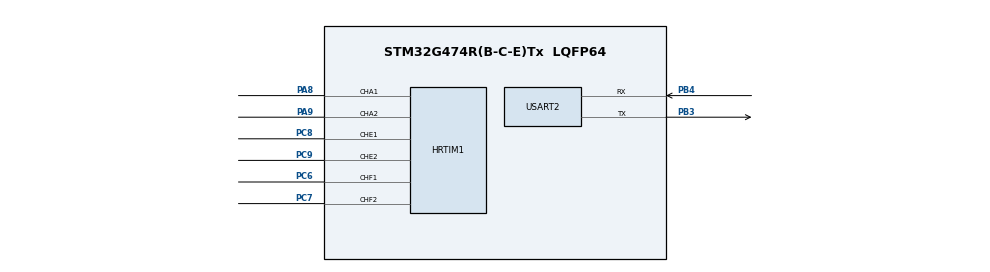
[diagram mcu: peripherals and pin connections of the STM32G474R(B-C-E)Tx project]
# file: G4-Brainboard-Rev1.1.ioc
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Dma.Request0=USART2_RX
Dma.USART2_RX.0.Direction=DMA_PERIPH_TO_MEMORY
Dma.USART2_RX.0.EventEnable=DISABLE
Dma.USART2_RX.0.Instance=DMA1_Channel1
Dma.USART2_RX.0.MemDataAlignment=DMA_MDATAALIGN_BYTE
Dma.USART2_RX.0.MemInc=DMA_MINC_ENABLE
Dma.USART2_RX.0.Mode=DMA_CIRCULAR
Dma.USART2_RX.0.PeriphDataAlignment=DMA_PDATAALIGN_BYTE
Dma.USART2_RX.0.PeriphInc=DMA_PINC_DISABLE
Dma.USART2_RX.0.Polarity=HAL_DMAMUX_REQ_GEN_RISING
Dma.USART2_RX.0.Priority=DMA_PRIORITY_LOW
Dma.USART2_RX.0.RequestNumber=1
Dma.USART2_RX.0.SignalID=NONE
Dma.USART2_RX.0.SyncEnable=DISABLE
Dma.USART2_RX.0.SyncPolarity=HAL_DMAMUX_SYNC_NO_EVENT
Dma.USART2_RX.0.SyncRequestNumber=1
Dma.USART2_RX.0.SyncSignalID=NONE
HRTIM1.CompareUnit1-Output_TA1TA2=HRTIM_COMPAREUNIT_1
HRTIM1.CompareUnit1-Output_TE1TE2=HRTIM_COMPAREUNIT_1
HRTIM1.CompareUnit1-Output_TF1TF2=HRTIM_COMPAREUNIT_1
HRTIM1.CompareValue1-Output_TA1TA2=48
HRTIM1.CompareValue1-Output_TE1TE2=27200
HRTIM1.CompareValue1-Output_TF1TF2=54352
HRTIM1.DeadTimeInsertion-Output_TA1TA2=HRTIM_TIMDEADTIMEINSERTION_ENABLED
HRTIM1.DeadTimeInsertion-Output_TE1TE2=HRTIM_TIMDEADTIMEINSERTION_ENABLED
HRTIM1.DeadTimeInsertion-Output_TF1TF2=HRTIM_TIMDEADTIMEINSERTION_ENABLED
HRTIM1.FallingValue-Output_TA1TA2=0x0
HRTIM1.IdleLevel1-Output_TF1TF2=HRTIM_OUTPUTIDLELEVEL_INACTIVE
HRTIM1.NumberResetSource1-Output_TA1TA2=1
HRTIM1.NumberResetSource1-Output_TE1TE2=1
HRTIM1.NumberResetSource1-Output_TF1TF2=1
HRTIM1.NumberSetSource1-Output_TA1TA2=0
HRTIM1.NumberSetSource1-Output_TE1TE2=0
HRTIM1.NumberSetSource1-Output_TF1TF2=0
HRTIM1.NumberUpdateTrigger-Output_TA1TA2=0
HRTIM1.Periode_TA=54400
HRTIM1.Periode_TE=54400
HRTIM1.Periode_TF=54400
HRTIM1.PreloadEnable-Output_TA1TA2=HRTIM_PRELOAD_ENABLED
HRTIM1.PreloadEnable-Output_TE1TE2=HRTIM_PRELOAD_ENABLED
HRTIM1.PreloadEnable-Output_TF1TF2=HRTIM_PRELOAD_ENABLED
HRTIM1.PrescalerDead-Output_TA1TA2=HRTIM_TIMDEADTIME_PRESCALERRATIO_DIV1
HRTIM1.PrescalerDead-Output_TE1TE2=HRTIM_TIMDEADTIME_PRESCALERRATIO_DIV1
HRTIM1.PrescalerDead-Output_TF1TF2=HRTIM_TIMDEADTIME_PRESCALERRATIO_DIV1
HRTIM1.PrescalerRatio_TA=HRTIM_PRESCALERRATIO_MUL16
HRTIM1.PrescalerRatio_TE=HRTIM_PRESCALERRATIO_MUL16
HRTIM1.PrescalerRatio_TF=HRTIM_PRESCALERRATIO_MUL16
HRTIM1.ResetOutput1_Source1-Output_TA1TA2=HRTIM_OUTPUTRESET_TIMCMP1
HRTIM1.ResetOutput1_Source1-Output_TE1TE2=HRTIM_OUTPUTRESET_TIMCMP1
HRTIM1.ResetOutput1_Source1-Output_TF1TF2=HRTIM_OUTPUTRESET_TIMCMP1
HRTIM1.ResetUpdate-Output_TA1TA2=HRTIM_TIMUPDATEONRESET_ENABLED
HRTIM1.ResetUpdate-Output_TE1TE2=HRTIM_TIMUPDATEONRESET_ENABLED
HRTIM1.ResetUpdate-Output_TF1TF2=HRTIM_TIMUPDATEONRESET_ENABLED
HRTIM1.RisingValue-Output_TA1TA2=0x0
HRTIM1.UpDownMode-Output_TA1TA2=HRTIM_TIMERUPDOWNMODE_UPDOWN
HRTIM1.UpDownMode-Output_TE1TE2=HRTIM_TIMERUPDOWNMODE_UPDOWN
HRTIM1.UpDownMode-Output_TF1TF2=HRTIM_TIMERUPDOWNMODE_UPDOWN
Mcu.Family=STM32G4
Mcu.Name=STM32G474R(B-C-E)Tx
Mcu.Package=LQFP64
NVIC.DMA1_Channel1_IRQn=true\:0\:0\:false\:false\:false\:true\:true\:true
NVIC.PriorityGroup=NVIC_PRIORITYGROUP_4
NVIC.USART2_IRQn=true\:0\:0\:false\:false\:false\:true\:true\:true
PA8.Mode=Output_TA1TA2
PA8.Signal=HRTIM1_CHA1
PA9.Mode=Output_TA1TA2
PA9.Signal=HRTIM1_CHA2
PB3.Mode=Asynchronous
PB3.Signal=USART2_TX
PB4.Mode=Asynchronous
PB4.Signal=USART2_RX
PC6.Mode=Output_TF1TF2
PC6.Signal=HRTIM1_CHF1
PC7.Mode=Output_TF1TF2
PC7.Signal=HRTIM1_CHF2
PC8.Mode=Output_TE1TE2
PC8.Signal=HRTIM1_CHE1
PC9.Mode=Output_TE1TE2
PC9.Signal=HRTIM1_CHE2
ProjectManager.HeapSize=0x200
ProjectManager.StackSize=0x400
ProjectManager.TargetToolchain=Makefile
RCC.ADC12Freq_Value=170000000
RCC.ADC345Freq_Value=170000000
RCC.AHBFreq_Value=170000000
RCC.APB1Freq_Value=170000000
RCC.APB1TimFreq_Value=170000000
RCC.APB2Freq_Value=170000000
RCC.APB2TimFreq_Value=170000000
RCC.CortexFreq_Value=170000000
RCC.EXTERNAL_CLOCK_VALUE=12288000
RCC.HCLKFreq_Value=170000000
RCC.HSE_VALUE=16000000
RCC.HSI48_VALUE=48000000
RCC.HSI_VALUE=16000000
RCC.LSE_VALUE=32768
RCC.PLLM=RCC_PLLM_DIV4
RCC.PLLN=85
RCC.SYSCLKFreq_VALUE=170000000
RCC.SYSCLKSource=RCC_SYSCLKSOURCE_PLLCLK
RCC.USBFreq_Value=170000000
RCC.VCOOutputFreq_Value=340000000
USART2.OneBitSampling=UART_ONE_BIT_SAMPLE_DISABLE
USART2.VirtualMode-Asynchronous=VM_ASYNC
VP_SYS_VS_DBSignals.Mode=DisableDeadBatterySignals
board=custom

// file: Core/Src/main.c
/* USER CODE BEGIN Header */
/**
  ******************************************************************************
  * @file           : main.c
  * @brief          : Main program body
  ******************************************************************************
  * @attention
  *
  * Copyright (c) 2026 STMicroelectronics.
  * All rights reserved.
  *
  * This software is licensed under terms that can be found in the LICENSE file
  * in the root directory of this software component.
  * If no LICENSE file comes with this software, it is provided AS-IS.
  *
  ******************************************************************************
  */
/* USER CODE END Header */
#include "main.h"
#include "dma.h"
#include "hrtim.h"
#include "usart.h"
#include "gpio.h"

/* USER CODE BEGIN PD */

/**
 * \brief           Calculate length of statically allocated array
 */
#define ARRAY_LEN(x) (sizeof(x) / sizeof((x)[0]))

/* USER CODE END PD */

/* USER CODE BEGIN PV */

/**
 * \brief           Circular DMA Buffer for USART2 RX
 */
uint8_t usart2_rx_dma_buff[256];

/* USER CODE END PV */

void SystemClock_Config(void);

int main(void)
{

  /* MCU Configuration--------------------------------------------------------*/

  /* Reset of all peripherals, Initializes the Flash interface and the Systick. */
  LL_APB2_GRP1_EnableClock(LL_APB2_GRP1_PERIPH_SYSCFG);
  LL_APB1_GRP1_EnableClock(LL_APB1_GRP1_PERIPH_PWR);

  /* System interrupt init*/
  NVIC_SetPriorityGrouping(NVIC_PRIORITYGROUP_4);

  /* SysTick_IRQn interrupt configuration */
  NVIC_SetPriority(SysTick_IRQn, NVIC_EncodePriority(NVIC_GetPriorityGrouping(),15, 0));

  /** Disable the internal Pull-Up in Dead Battery pins of UCPD peripheral
  */
  LL_PWR_DisableUCPDDeadBattery();

  /* Configure the system clock */
  SystemClock_Config();

  /* Initialize all configured peripherals */
  MX_GPIO_Init();
  MX_DMA_Init();
  MX_HRTIM1_Init();
  MX_USART2_UART_Init();
  /* USER CODE BEGIN 2 */

  LL_HRTIM_TIM_CounterEnable(HRTIM1,LL_HRTIM_TIMER_A | LL_HRTIM_TIMER_E | LL_HRTIM_TIMER_F);
  LL_HRTIM_EnableOutput(HRTIM1, LL_HRTIM_OUTPUT_TA1|LL_HRTIM_OUTPUT_TA2);
  LL_HRTIM_EnableOutput(HRTIM1, LL_HRTIM_OUTPUT_TE1|LL_HRTIM_OUTPUT_TE2);
  LL_HRTIM_EnableOutput(HRTIM1, LL_HRTIM_OUTPUT_TF1|LL_HRTIM_OUTPUT_TF2);

  /* USER CODE END 2 */

  /* Infinite loop */
  while (1)
  {

  }
}

void SystemClock_Config(void)
{
  LL_FLASH_SetLatency(LL_FLASH_LATENCY_4);
  while(LL_FLASH_GetLatency() != LL_FLASH_LATENCY_4)
  {
  }
  LL_PWR_EnableRange1BoostMode();
  LL_RCC_HSI_Enable();
   /* Wait till HSI is ready */
  while(LL_RCC_HSI_IsReady() != 1)
  {
  }

  LL_RCC_HSI_SetCalibTrimming(64);
  LL_RCC_PLL_ConfigDomain_SYS(LL_RCC_PLLSOURCE_HSI, LL_RCC_PLLM_DIV_4, 85, LL_RCC_PLLR_DIV_2);
  LL_RCC_PLL_EnableDomain_SYS();
  LL_RCC_PLL_Enable();
   /* Wait till PLL is ready */
  while(LL_RCC_PLL_IsReady() != 1)
  {
  }

  LL_RCC_SetSysClkSource(LL_RCC_SYS_CLKSOURCE_PLL);
  LL_RCC_SetAHBPrescaler(LL_RCC_SYSCLK_DIV_2);
   /* Wait till System clock is ready */
  while(LL_RCC_GetSysClkSource() != LL_RCC_SYS_CLKSOURCE_STATUS_PLL)
  {
  }

  /* Insure 1us transition state at intermediate medium speed clock*/
  for (__IO uint32_t i = (170 >> 1); i !=0; i--);

  /* Set AHB prescaler*/
  LL_RCC_SetAHBPrescaler(LL_RCC_SYSCLK_DIV_1);
  LL_RCC_SetAPB1Prescaler(LL_RCC_APB1_DIV_1);
  LL_RCC_SetAPB2Prescaler(LL_RCC_APB2_DIV_1);

  LL_Init1msTick(170000000);

  LL_SetSystemCoreClock(170000000);
}

void Error_Handler(void)
{
  __disable_irq();
  while (1)
  {
  }
}
